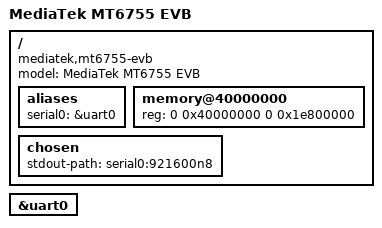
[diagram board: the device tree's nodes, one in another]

/dts-v1/;
#include "mediatek/mt6755.dtsi"

/ {
	model = "MediaTek MT6755 EVB";
	compatible = "mediatek,mt6755-evb", "mediatek,mt6755";

	aliases {
		serial0 = &uart0;
	};

	memory@40000000 {
		device_type = "memory";
		reg = <0 0x40000000 0 0x1e800000>;
	};

	chosen {
		stdout-path = "serial0:921600n8";
	};
};

&uart0 {
	status = "okay";
};
